# ESP32-S3 register map
Vendor: ESPRESSIF SYSTEMS (SHANGHAI) CO., LTD.; Series: ESP32 S-Series; File version: 22
CPU: Xtensa LX7 r0p0, little endian, no MPU, FPU, 0 interrupt priority bits
Address unit: 32 bits
Registers are 32-bit, read-write, reset 0x0 unless marked. A register's access mark holds for its fields unless they carry their own. Offsets are from the block's base; [hi:lo] are bit positions; {n}, {i} and the like mark numbered series.

## SENSITIVE (part 2 of 2) — SENSITIVE Peripheral
Base 0x600C1000
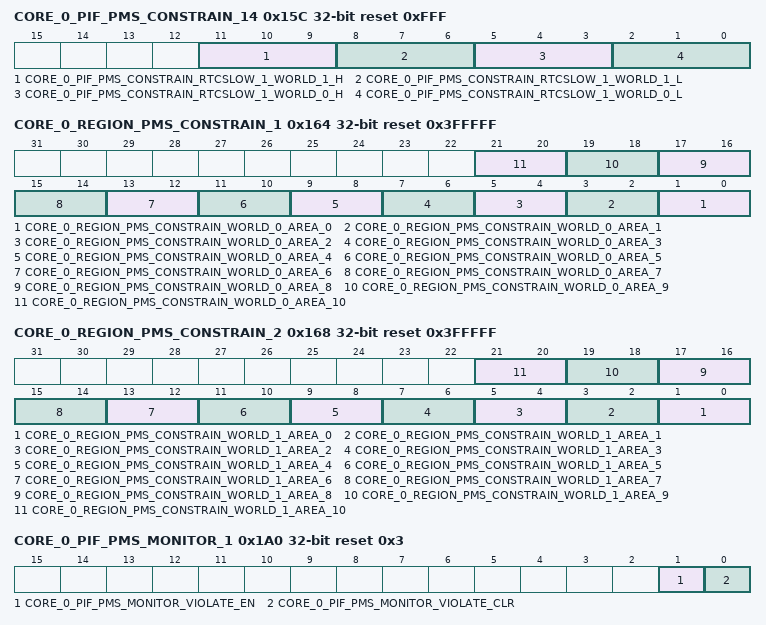
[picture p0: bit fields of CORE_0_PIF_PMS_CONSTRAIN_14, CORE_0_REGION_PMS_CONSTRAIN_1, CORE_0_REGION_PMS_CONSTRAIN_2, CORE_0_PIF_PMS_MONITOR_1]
0x15C CORE_0_PIF_PMS_CONSTRAIN_14 reset 0xFFF — Core0 access peripherals permission configuration register 14.
  [11:9] CORE_0_PIF_PMS_CONSTRAIN_RTCSLOW_1_WORLD_1_H — RTCSlow_1 memory high region permission in world 1 for core0.
  [8:6] CORE_0_PIF_PMS_CONSTRAIN_RTCSLOW_1_WORLD_1_L — RTCSlow_1 memory low region permission in world 1 for core0.
  [5:3] CORE_0_PIF_PMS_CONSTRAIN_RTCSLOW_1_WORLD_0_H — RTCSlow_1 memory high region permission in world 0 for core0.
  [2:0] CORE_0_PIF_PMS_CONSTRAIN_RTCSLOW_1_WORLD_0_L — RTCSlow_1 memory low region permission in world 0 for core0.
0x160 CORE_0_REGION_PMS_CONSTRAIN_0 — Core0 region permission register 0.
  [0] CORE_0_REGION_PMS_CONSTRAIN_LOCK — Set 1 to lock core0 region permission registers.
0x164 CORE_0_REGION_PMS_CONSTRAIN_1 reset 0x3FFFFF — Core0 region permission register 1.
  [2n+1:2n] CORE_0_REGION_PMS_CONSTRAIN_WORLD_0_AREA_{n} (n=0..10) — Region {n} permission in world 0 for core0.
0x168 CORE_0_REGION_PMS_CONSTRAIN_2 reset 0x3FFFFF — Core0 region permission register 2.
  [2n+1:2n] CORE_0_REGION_PMS_CONSTRAIN_WORLD_1_AREA_{n} (n=0..10) — Region {n} permission in world 1 for core0.
0x16C CORE_0_REGION_PMS_CONSTRAIN_3 — Core0 region permission register 3.
  [29:0] CORE_0_REGION_PMS_CONSTRAIN_ADDR_0 — Region 0 start address for core0.
{0x160+4i} CORE_0_REGION_PMS_CONSTRAIN_{i} (i=4..13) — Core0 region permission register {i}.
  [29:0] CORE_0_REGION_PMS_CONSTRAIN_ADDR_{i-3} — Region {i-4} end address and Region {i-3} start address for core0.
0x198 CORE_0_REGION_PMS_CONSTRAIN_14 — Core0 region permission register 14.
  [29:0] CORE_0_REGION_PMS_CONSTRAIN_ADDR_11 — Region 10 end address for core0.
0x19C CORE_0_PIF_PMS_MONITOR_0 — Core0 permission report register 0.
  [0] CORE_0_PIF_PMS_MONITOR_LOCK — Set 1 to lock core0 permission report registers.
0x1A0 CORE_0_PIF_PMS_MONITOR_1 reset 0x3 — Core0 permission report register 1.
  [1] CORE_0_PIF_PMS_MONITOR_VIOLATE_EN — Set 1 to enable interrupt that core0 initiate illegal PIF bus access.
  [0] CORE_0_PIF_PMS_MONITOR_VIOLATE_CLR — Set 1 to clear interrupt that core0 initiate illegal PIF bus access.
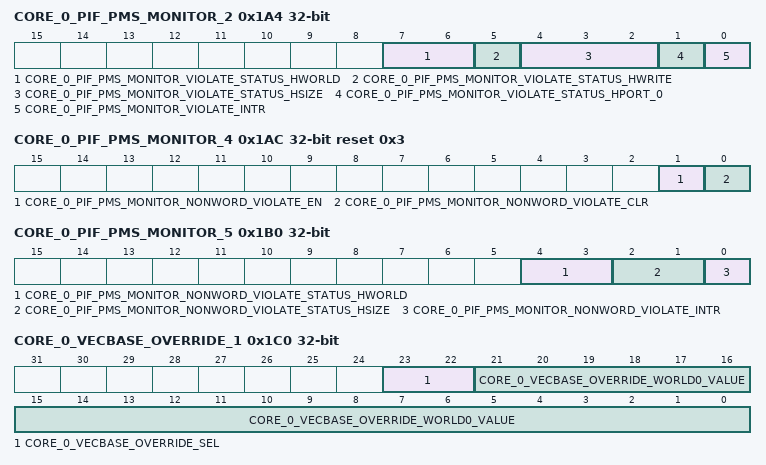
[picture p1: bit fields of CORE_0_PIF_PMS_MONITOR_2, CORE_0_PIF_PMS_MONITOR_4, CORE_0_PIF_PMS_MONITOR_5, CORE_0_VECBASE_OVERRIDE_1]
0x1A4 CORE_0_PIF_PMS_MONITOR_2 ro — Core0 permission report register 2.
  [7:6] CORE_0_PIF_PMS_MONITOR_VIOLATE_STATUS_HWORLD — Record world information when core0 initiate illegal access.
  [5] CORE_0_PIF_PMS_MONITOR_VIOLATE_STATUS_HWRITE — Record access direction when core0 initiate illegal access.
  [4:2] CORE_0_PIF_PMS_MONITOR_VIOLATE_STATUS_HSIZE — Record access type when core0 initate illegal access.
  [1] CORE_0_PIF_PMS_MONITOR_VIOLATE_STATUS_HPORT_0 — Record hport information when core0 initiate illegal access.
  [0] CORE_0_PIF_PMS_MONITOR_VIOLATE_INTR — Record core0 illegal access interrupt state.
0x1A8 CORE_0_PIF_PMS_MONITOR_3 ro — Core0 permission report register 3.
  [31:0] CORE_0_PIF_PMS_MONITOR_VIOLATE_STATUS_HADDR — Record address information when core0 initiate illegal access.
0x1AC CORE_0_PIF_PMS_MONITOR_4 reset 0x3 — Core0 permission report register 4.
  [1] CORE_0_PIF_PMS_MONITOR_NONWORD_VIOLATE_EN — Set 1 to enable interrupt that core0 initiate unsupported access type.
  [0] CORE_0_PIF_PMS_MONITOR_NONWORD_VIOLATE_CLR — Set 1 to clear interrupt that core0 initiate unsupported access type.
0x1B0 CORE_0_PIF_PMS_MONITOR_5 ro — Core0 permission report register 5.
  [4:3] CORE_0_PIF_PMS_MONITOR_NONWORD_VIOLATE_STATUS_HWORLD — Record world information when core0 initiate unsupported access type.
  [2:1] CORE_0_PIF_PMS_MONITOR_NONWORD_VIOLATE_STATUS_HSIZE — Record access type when core0 initiate unsupported access type.
  [0] CORE_0_PIF_PMS_MONITOR_NONWORD_VIOLATE_INTR — Record core0 unsupported access type interrupt state.
0x1B4 CORE_0_PIF_PMS_MONITOR_6 ro — Core0 permission report register 6.
  [31:0] CORE_0_PIF_PMS_MONITOR_NONWORD_VIOLATE_STATUS_HADDR — Record address information when core0 initiate unsupported access type.
0x1B8 CORE_0_VECBASE_OVERRIDE_LOCK — core0 vecbase override configuration register 0
  [0] CORE_0_VECBASE_OVERRIDE_LOCK — Set 1 to lock core0 vecbase configuration register
0x1BC CORE_0_VECBASE_OVERRIDE_0 reset 0x1 — core0 vecbase override configuration register 0
  [0] CORE_0_VECBASE_WORLD_MASK — Set 1 to mask world, then only world0_value will work.
0x1C0 CORE_0_VECBASE_OVERRIDE_1 — core0 vecbase override configuration register 1
  [23:22] CORE_0_VECBASE_OVERRIDE_SEL — Set 0x3 to sel vecbase_override to override vecbase register.
  [21:0] CORE_0_VECBASE_OVERRIDE_WORLD0_VALUE — world0 vecbase_override register, when core0 in world0 use this register to override vecbase register.
0x1C4 CORE_0_VECBASE_OVERRIDE_2 — core0 vecbase override configuration register 1
  [21:0] CORE_0_VECBASE_OVERRIDE_WORLD1_VALUE — world1 vecbase_override register, when core0 in world1 use this register to override vecbase register.
0x1C8 CORE_0_TOOMANYEXCEPTIONS_M_OVERRIDE_0 — core0 toomanyexception override configuration register 0.
  [0] CORE_0_TOOMANYEXCEPTIONS_M_OVERRIDE_LOCK — Set 1 to lock core0 toomanyexception override configuration register
0x1CC CORE_0_TOOMANYEXCEPTIONS_M_OVERRIDE_1 reset 0x1 — core0 toomanyexception override configuration register 1.
  [0] CORE_0_TOOMANYEXCEPTIONS_M_OVERRIDE — Set 1 to mask toomanyexception.
0x1D0 CORE_1_PIF_PMS_CONSTRAIN_0 — Core1 access peripherals permission configuration register 0.
  [0] CORE_1_PIF_PMS_CONSTRAIN_LOCK — Set 1 to lock core1 pif permission configuration register.
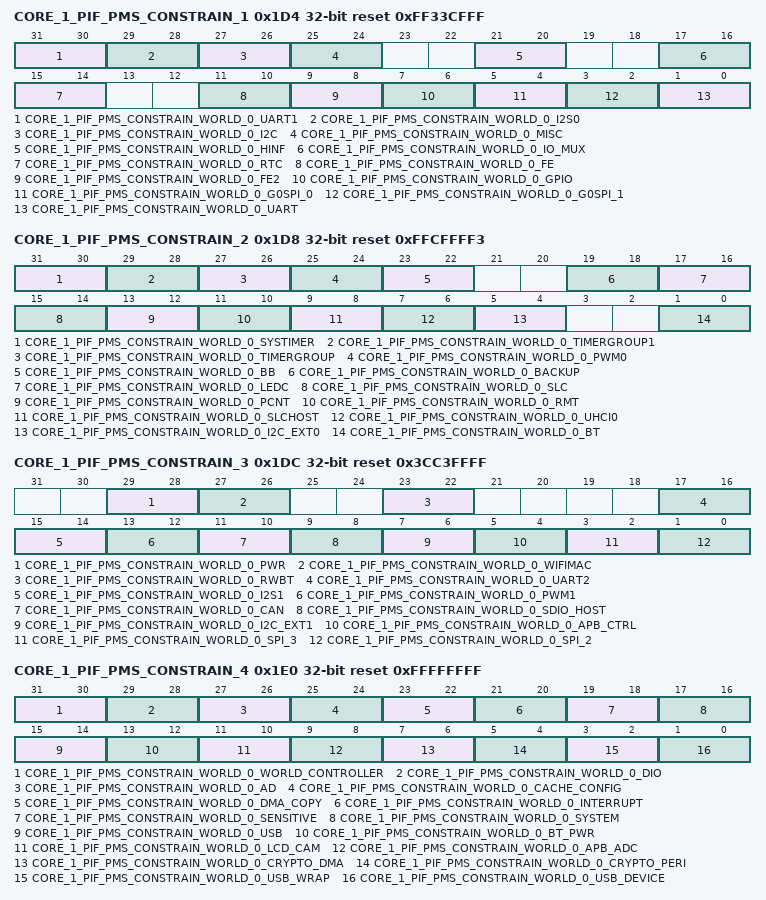
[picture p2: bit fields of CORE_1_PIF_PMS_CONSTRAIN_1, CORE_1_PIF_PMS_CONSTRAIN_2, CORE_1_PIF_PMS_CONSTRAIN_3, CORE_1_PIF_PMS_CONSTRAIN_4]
0x1D4 CORE_1_PIF_PMS_CONSTRAIN_1 reset 0xFF33CFFF — Core1 access peripherals permission configuration register 1.
  [31:30] CORE_1_PIF_PMS_CONSTRAIN_WORLD_0_UART1 — Core1 access uart1 permission in world0.
  [29:28] CORE_1_PIF_PMS_CONSTRAIN_WORLD_0_I2S0 — Core1 access i2s0 permission in world0.
  [27:26] CORE_1_PIF_PMS_CONSTRAIN_WORLD_0_I2C — Core1 access i2c permission in world0.
  [25:24] CORE_1_PIF_PMS_CONSTRAIN_WORLD_0_MISC — Core1 access misc permission in world0.
  [21:20] CORE_1_PIF_PMS_CONSTRAIN_WORLD_0_HINF — Core1 access hinf permission in world0.
  [17:16] CORE_1_PIF_PMS_CONSTRAIN_WORLD_0_IO_MUX — Core1 access io_mux permission in world0.
  [15:14] CORE_1_PIF_PMS_CONSTRAIN_WORLD_0_RTC — Core1 access rtc permission in world0.
  [11:10] CORE_1_PIF_PMS_CONSTRAIN_WORLD_0_FE — Core1 access fe permission in world0.
  [9:8] CORE_1_PIF_PMS_CONSTRAIN_WORLD_0_FE2 — Core1 access fe2 permission in world0.
  [7:6] CORE_1_PIF_PMS_CONSTRAIN_WORLD_0_GPIO — Core1 access gpio permission in world0.
  [5:4] CORE_1_PIF_PMS_CONSTRAIN_WORLD_0_G0SPI_0 — Core1 access g0spi_0 permission in world0.
  [3:2] CORE_1_PIF_PMS_CONSTRAIN_WORLD_0_G0SPI_1 — Core1 access g0spi_1 permission in world0.
  [1:0] CORE_1_PIF_PMS_CONSTRAIN_WORLD_0_UART — Core1 access uart permission in world0.
0x1D8 CORE_1_PIF_PMS_CONSTRAIN_2 reset 0xFFCFFFF3 — Core1 access peripherals permission configuration register 2.
  [31:30] CORE_1_PIF_PMS_CONSTRAIN_WORLD_0_SYSTIMER — Core1 access systimer permission in world0.
  [29:28] CORE_1_PIF_PMS_CONSTRAIN_WORLD_0_TIMERGROUP1 — Core1 access timergroup1 permission in world0.
  [27:26] CORE_1_PIF_PMS_CONSTRAIN_WORLD_0_TIMERGROUP — Core1 access timergroup permission in world0.
  [25:24] CORE_1_PIF_PMS_CONSTRAIN_WORLD_0_PWM0 — Core1 access pwm0 permission in world0.
  [23:22] CORE_1_PIF_PMS_CONSTRAIN_WORLD_0_BB — Core1 access bb permission in world0.
  [19:18] CORE_1_PIF_PMS_CONSTRAIN_WORLD_0_BACKUP — Core1 access backup permission in world0.
  [17:16] CORE_1_PIF_PMS_CONSTRAIN_WORLD_0_LEDC — Core1 access ledc permission in world0.
  [15:14] CORE_1_PIF_PMS_CONSTRAIN_WORLD_0_SLC — Core1 access slc permission in world0.
  [13:12] CORE_1_PIF_PMS_CONSTRAIN_WORLD_0_PCNT — Core1 access pcnt permission in world0.
  [11:10] CORE_1_PIF_PMS_CONSTRAIN_WORLD_0_RMT — Core1 access rmt permission in world0.
  [9:8] CORE_1_PIF_PMS_CONSTRAIN_WORLD_0_SLCHOST — Core1 access slchost permission in world0.
  [7:6] CORE_1_PIF_PMS_CONSTRAIN_WORLD_0_UHCI0 — Core1 access uhci0 permission in world0.
  [5:4] CORE_1_PIF_PMS_CONSTRAIN_WORLD_0_I2C_EXT0 — Core1 access i2c_ext0 permission in world0.
  [1:0] CORE_1_PIF_PMS_CONSTRAIN_WORLD_0_BT — Core1 access bt permission in world0.
0x1DC CORE_1_PIF_PMS_CONSTRAIN_3 reset 0x3CC3FFFF — Core1 access peripherals permission configuration register 3.
  [29:28] CORE_1_PIF_PMS_CONSTRAIN_WORLD_0_PWR — Core1 access pwr permission in world0.
  [27:26] CORE_1_PIF_PMS_CONSTRAIN_WORLD_0_WIFIMAC — Core1 access wifimac permission in world0.
  [23:22] CORE_1_PIF_PMS_CONSTRAIN_WORLD_0_RWBT — Core1 access rwbt permission in world0.
  [17:16] CORE_1_PIF_PMS_CONSTRAIN_WORLD_0_UART2 — Core1 access uart2 permission in world0.
  [15:14] CORE_1_PIF_PMS_CONSTRAIN_WORLD_0_I2S1 — Core1 access i2s1 permission in world0.
  [13:12] CORE_1_PIF_PMS_CONSTRAIN_WORLD_0_PWM1 — Core1 access pwm1 permission in world0.
  [11:10] CORE_1_PIF_PMS_CONSTRAIN_WORLD_0_CAN — Core1 access can permission in world0.
  [9:8] CORE_1_PIF_PMS_CONSTRAIN_WORLD_0_SDIO_HOST — Core1 access sdio_host permission in world0.
  [7:6] CORE_1_PIF_PMS_CONSTRAIN_WORLD_0_I2C_EXT1 — Core1 access i2c_ext1 permission in world0.
  [5:4] CORE_1_PIF_PMS_CONSTRAIN_WORLD_0_APB_CTRL — Core1 access apb_ctrl permission in world0.
  [3:2] CORE_1_PIF_PMS_CONSTRAIN_WORLD_0_SPI_3 — Core1 access spi_3 permission in world0.
  [1:0] CORE_1_PIF_PMS_CONSTRAIN_WORLD_0_SPI_2 — Core1 access spi_2 permission in world0.
0x1E0 CORE_1_PIF_PMS_CONSTRAIN_4 reset 0xFFFFFFFF — Core1 access peripherals permission configuration register 4.
  [31:30] CORE_1_PIF_PMS_CONSTRAIN_WORLD_0_WORLD_CONTROLLER — Core1 access world_controller permission in world0.
  [29:28] CORE_1_PIF_PMS_CONSTRAIN_WORLD_0_DIO — Core1 access dio permission in world0.
  [27:26] CORE_1_PIF_PMS_CONSTRAIN_WORLD_0_AD — Core1 access ad permission in world0.
  [25:24] CORE_1_PIF_PMS_CONSTRAIN_WORLD_0_CACHE_CONFIG — Core1 access cache_config permission in world0.
  [23:22] CORE_1_PIF_PMS_CONSTRAIN_WORLD_0_DMA_COPY — Core1 access dma_copy permission in world0.
  [21:20] CORE_1_PIF_PMS_CONSTRAIN_WORLD_0_INTERRUPT — Core1 access interrupt permission in world0.
  [19:18] CORE_1_PIF_PMS_CONSTRAIN_WORLD_0_SENSITIVE — Core1 access sensitive permission in world0.
  [17:16] CORE_1_PIF_PMS_CONSTRAIN_WORLD_0_SYSTEM — Core1 access system permission in world0.
  [15:14] CORE_1_PIF_PMS_CONSTRAIN_WORLD_0_USB — Core1 access usb permission in world0.
  [13:12] CORE_1_PIF_PMS_CONSTRAIN_WORLD_0_BT_PWR — Core1 access bt_pwr permission in world0.
  [11:10] CORE_1_PIF_PMS_CONSTRAIN_WORLD_0_LCD_CAM — Core1 access lcd_cam permission in world0.
  [9:8] CORE_1_PIF_PMS_CONSTRAIN_WORLD_0_APB_ADC — Core1 access apb_adc permission in world0.
  [7:6] CORE_1_PIF_PMS_CONSTRAIN_WORLD_0_CRYPTO_DMA — Core1 access crypto_dma permission in world0.
  [5:4] CORE_1_PIF_PMS_CONSTRAIN_WORLD_0_CRYPTO_PERI — Core1 access crypto_peri permission in world0.
  [3:2] CORE_1_PIF_PMS_CONSTRAIN_WORLD_0_USB_WRAP — Core1 access usb_wrap permission in world0.
  [1:0] CORE_1_PIF_PMS_CONSTRAIN_WORLD_0_USB_DEVICE — Core1 access usb_device permission in world0.
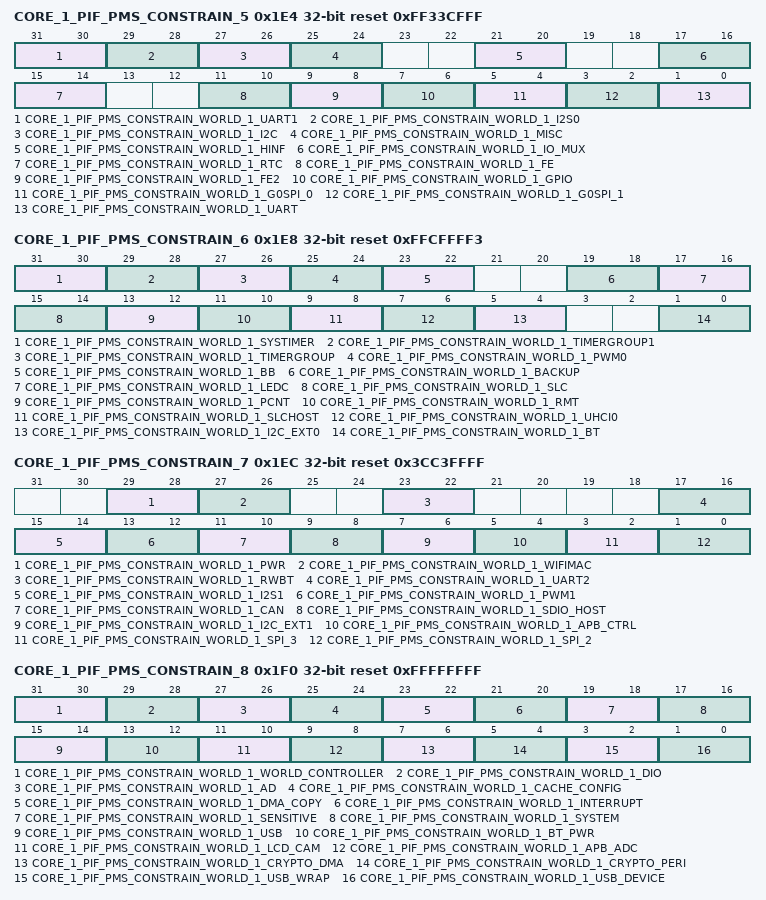
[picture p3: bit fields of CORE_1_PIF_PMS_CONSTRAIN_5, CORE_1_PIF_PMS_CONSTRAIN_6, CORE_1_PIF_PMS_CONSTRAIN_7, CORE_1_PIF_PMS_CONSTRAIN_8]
0x1E4 CORE_1_PIF_PMS_CONSTRAIN_5 reset 0xFF33CFFF — Core1 access peripherals permission configuration register 5.
  [31:30] CORE_1_PIF_PMS_CONSTRAIN_WORLD_1_UART1 — Core1 access uart1 permission in world1.
  [29:28] CORE_1_PIF_PMS_CONSTRAIN_WORLD_1_I2S0 — Core1 access i2s0 permission in world1.
  [27:26] CORE_1_PIF_PMS_CONSTRAIN_WORLD_1_I2C — Core1 access i2c permission in world1.
  [25:24] CORE_1_PIF_PMS_CONSTRAIN_WORLD_1_MISC — Core1 access misc permission in world1.
  [21:20] CORE_1_PIF_PMS_CONSTRAIN_WORLD_1_HINF — Core1 access hinf permission in world1.
  [17:16] CORE_1_PIF_PMS_CONSTRAIN_WORLD_1_IO_MUX — Core1 access io_mux permission in world1.
  [15:14] CORE_1_PIF_PMS_CONSTRAIN_WORLD_1_RTC — Core1 access rtc permission in world1.
  [11:10] CORE_1_PIF_PMS_CONSTRAIN_WORLD_1_FE — Core1 access fe permission in world1.
  [9:8] CORE_1_PIF_PMS_CONSTRAIN_WORLD_1_FE2 — Core1 access fe2 permission in world1.
  [7:6] CORE_1_PIF_PMS_CONSTRAIN_WORLD_1_GPIO — Core1 access gpio permission in world1.
  [5:4] CORE_1_PIF_PMS_CONSTRAIN_WORLD_1_G0SPI_0 — Core1 access g0spi_0 permission in world1.
  [3:2] CORE_1_PIF_PMS_CONSTRAIN_WORLD_1_G0SPI_1 — Core1 access g0spi_1 permission in world1.
  [1:0] CORE_1_PIF_PMS_CONSTRAIN_WORLD_1_UART — Core1 access uart permission in world1.
0x1E8 CORE_1_PIF_PMS_CONSTRAIN_6 reset 0xFFCFFFF3 — Core1 access peripherals permission configuration register 6.
  [31:30] CORE_1_PIF_PMS_CONSTRAIN_WORLD_1_SYSTIMER — Core1 access systimer permission in world1.
  [29:28] CORE_1_PIF_PMS_CONSTRAIN_WORLD_1_TIMERGROUP1 — Core1 access timergroup1 permission in world1.
  [27:26] CORE_1_PIF_PMS_CONSTRAIN_WORLD_1_TIMERGROUP — Core1 access timergroup permission in world1.
  [25:24] CORE_1_PIF_PMS_CONSTRAIN_WORLD_1_PWM0 — Core1 access pwm0 permission in world1.
  [23:22] CORE_1_PIF_PMS_CONSTRAIN_WORLD_1_BB — Core1 access bb permission in world1.
  [19:18] CORE_1_PIF_PMS_CONSTRAIN_WORLD_1_BACKUP — Core1 access backup permission in world1.
  [17:16] CORE_1_PIF_PMS_CONSTRAIN_WORLD_1_LEDC — Core1 access ledc permission in world1.
  [15:14] CORE_1_PIF_PMS_CONSTRAIN_WORLD_1_SLC — Core1 access slc permission in world1.
  [13:12] CORE_1_PIF_PMS_CONSTRAIN_WORLD_1_PCNT — Core1 access pcnt permission in world1.
  [11:10] CORE_1_PIF_PMS_CONSTRAIN_WORLD_1_RMT — Core1 access rmt permission in world1.
  [9:8] CORE_1_PIF_PMS_CONSTRAIN_WORLD_1_SLCHOST — Core1 access slchost permission in world1.
  [7:6] CORE_1_PIF_PMS_CONSTRAIN_WORLD_1_UHCI0 — Core1 access uhci0 permission in world1.
  [5:4] CORE_1_PIF_PMS_CONSTRAIN_WORLD_1_I2C_EXT0 — Core1 access i2c_ext0 permission in world1.
  [1:0] CORE_1_PIF_PMS_CONSTRAIN_WORLD_1_BT — Core1 access bt permission in world1.
0x1EC CORE_1_PIF_PMS_CONSTRAIN_7 reset 0x3CC3FFFF — Core1 access peripherals permission configuration register 7.
  [29:28] CORE_1_PIF_PMS_CONSTRAIN_WORLD_1_PWR — Core1 access pwr permission in world1.
  [27:26] CORE_1_PIF_PMS_CONSTRAIN_WORLD_1_WIFIMAC — Core1 access wifimac permission in world1.
  [23:22] CORE_1_PIF_PMS_CONSTRAIN_WORLD_1_RWBT — Core1 access rwbt permission in world1.
  [17:16] CORE_1_PIF_PMS_CONSTRAIN_WORLD_1_UART2 — Core1 access uart2 permission in world1.
  [15:14] CORE_1_PIF_PMS_CONSTRAIN_WORLD_1_I2S1 — Core1 access i2s1 permission in world1.
  [13:12] CORE_1_PIF_PMS_CONSTRAIN_WORLD_1_PWM1 — Core1 access pwm1 permission in world1.
  [11:10] CORE_1_PIF_PMS_CONSTRAIN_WORLD_1_CAN — Core1 access can permission in world1.
  [9:8] CORE_1_PIF_PMS_CONSTRAIN_WORLD_1_SDIO_HOST — Core1 access sdio_host permission in world1.
  [7:6] CORE_1_PIF_PMS_CONSTRAIN_WORLD_1_I2C_EXT1 — Core1 access i2c_ext1 permission in world1.
  [5:4] CORE_1_PIF_PMS_CONSTRAIN_WORLD_1_APB_CTRL — Core1 access apb_ctrl permission in world1.
  [3:2] CORE_1_PIF_PMS_CONSTRAIN_WORLD_1_SPI_3 — Core1 access spi_3 permission in world1.
  [1:0] CORE_1_PIF_PMS_CONSTRAIN_WORLD_1_SPI_2 — Core1 access spi_2 permission in world1.
0x1F0 CORE_1_PIF_PMS_CONSTRAIN_8 reset 0xFFFFFFFF — Core1 access peripherals permission configuration register 8.
  [31:30] CORE_1_PIF_PMS_CONSTRAIN_WORLD_1_WORLD_CONTROLLER — Core1 access world_controller permission in world1.
  [29:28] CORE_1_PIF_PMS_CONSTRAIN_WORLD_1_DIO — Core1 access dio permission in world1.
  [27:26] CORE_1_PIF_PMS_CONSTRAIN_WORLD_1_AD — Core1 access ad permission in world1.
  [25:24] CORE_1_PIF_PMS_CONSTRAIN_WORLD_1_CACHE_CONFIG — Core1 access cache_config permission in world1.
  [23:22] CORE_1_PIF_PMS_CONSTRAIN_WORLD_1_DMA_COPY — Core1 access dma_copy permission in world1.
  [21:20] CORE_1_PIF_PMS_CONSTRAIN_WORLD_1_INTERRUPT — Core1 access interrupt permission in world1.
  [19:18] CORE_1_PIF_PMS_CONSTRAIN_WORLD_1_SENSITIVE — Core1 access sensitive permission in world1.
  [17:16] CORE_1_PIF_PMS_CONSTRAIN_WORLD_1_SYSTEM — Core1 access system permission in world1.
  [15:14] CORE_1_PIF_PMS_CONSTRAIN_WORLD_1_USB — Core1 access usb permission in world1.
  [13:12] CORE_1_PIF_PMS_CONSTRAIN_WORLD_1_BT_PWR — Core1 access bt_pwr permission in world1.
  [11:10] CORE_1_PIF_PMS_CONSTRAIN_WORLD_1_LCD_CAM — Core1 access lcd_cam permission in world1.
  [9:8] CORE_1_PIF_PMS_CONSTRAIN_WORLD_1_APB_ADC — Core1 access apb_adc permission in world1.
  [7:6] CORE_1_PIF_PMS_CONSTRAIN_WORLD_1_CRYPTO_DMA — Core1 access crypto_dma permission in world1.
  [5:4] CORE_1_PIF_PMS_CONSTRAIN_WORLD_1_CRYPTO_PERI — Core1 access crypto_peri permission in world1.
  [3:2] CORE_1_PIF_PMS_CONSTRAIN_WORLD_1_USB_WRAP — Core1 access usb_wrap permission in world1.
  [1:0] CORE_1_PIF_PMS_CONSTRAIN_WORLD_1_USB_DEVICE — Core1 access usb_device permission in world1.
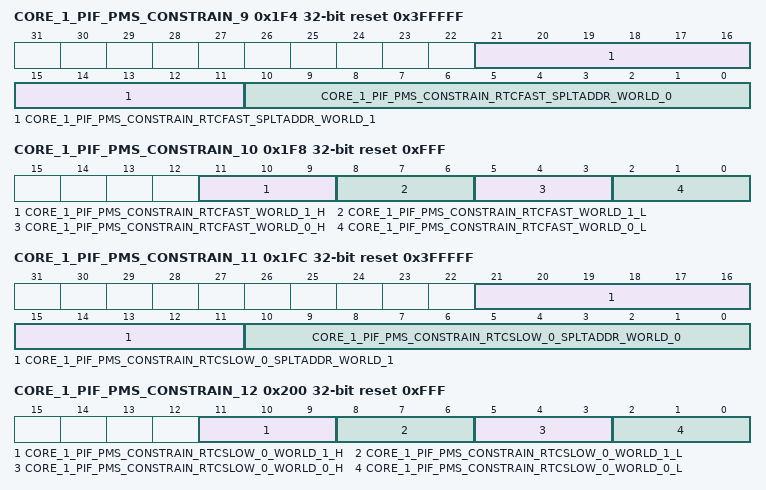
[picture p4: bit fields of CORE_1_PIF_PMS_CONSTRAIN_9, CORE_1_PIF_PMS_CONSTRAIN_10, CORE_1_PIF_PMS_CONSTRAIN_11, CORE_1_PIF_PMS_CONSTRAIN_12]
0x1F4 CORE_1_PIF_PMS_CONSTRAIN_9 reset 0x3FFFFF — Core1 access peripherals permission configuration register 9.
  [21:11] CORE_1_PIF_PMS_CONSTRAIN_RTCFAST_SPLTADDR_WORLD_1 — RTCFast memory split address in world 1 for core1.
  [10:0] CORE_1_PIF_PMS_CONSTRAIN_RTCFAST_SPLTADDR_WORLD_0 — RTCFast memory split address in world 0 for core1.
0x1F8 CORE_1_PIF_PMS_CONSTRAIN_10 reset 0xFFF — core1 access peripherals permission configuration register 10.
  [11:9] CORE_1_PIF_PMS_CONSTRAIN_RTCFAST_WORLD_1_H — RTCFast memory high region permission in world 1 for core1.
  [8:6] CORE_1_PIF_PMS_CONSTRAIN_RTCFAST_WORLD_1_L — RTCFast memory low region permission in world 1 for core1.
  [5:3] CORE_1_PIF_PMS_CONSTRAIN_RTCFAST_WORLD_0_H — RTCFast memory high region permission in world 0 for core1.
  [2:0] CORE_1_PIF_PMS_CONSTRAIN_RTCFAST_WORLD_0_L — RTCFast memory low region permission in world 0 for core1.
0x1FC CORE_1_PIF_PMS_CONSTRAIN_11 reset 0x3FFFFF — core1 access peripherals permission configuration register 11.
  [21:11] CORE_1_PIF_PMS_CONSTRAIN_RTCSLOW_0_SPLTADDR_WORLD_1 — RTCSlow_0 memory split address in world 1 for core1.
  [10:0] CORE_1_PIF_PMS_CONSTRAIN_RTCSLOW_0_SPLTADDR_WORLD_0 — RTCSlow_0 memory split address in world 0 for core1.
0x200 CORE_1_PIF_PMS_CONSTRAIN_12 reset 0xFFF — core1 access peripherals permission configuration register 12.
  [11:9] CORE_1_PIF_PMS_CONSTRAIN_RTCSLOW_0_WORLD_1_H — RTCSlow_0 memory high region permission in world 1 for core1.
  [8:6] CORE_1_PIF_PMS_CONSTRAIN_RTCSLOW_0_WORLD_1_L — RTCSlow_0 memory low region permission in world 1 for core1.
  [5:3] CORE_1_PIF_PMS_CONSTRAIN_RTCSLOW_0_WORLD_0_H — RTCSlow_0 memory high region permission in world 0 for core1.
  [2:0] CORE_1_PIF_PMS_CONSTRAIN_RTCSLOW_0_WORLD_0_L — RTCSlow_0 memory low region permission in world 0 for core1.
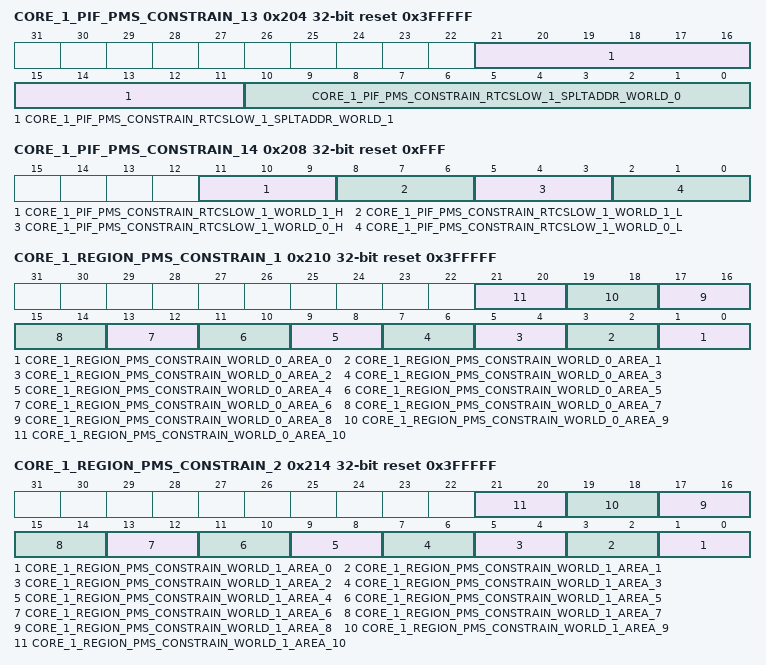
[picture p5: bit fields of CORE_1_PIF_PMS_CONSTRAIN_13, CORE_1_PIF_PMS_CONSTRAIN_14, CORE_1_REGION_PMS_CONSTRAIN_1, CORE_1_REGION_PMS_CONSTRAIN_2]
0x204 CORE_1_PIF_PMS_CONSTRAIN_13 reset 0x3FFFFF — core1 access peripherals permission configuration register 13.
  [21:11] CORE_1_PIF_PMS_CONSTRAIN_RTCSLOW_1_SPLTADDR_WORLD_1 — RTCSlow_1 memory split address in world 1 for core1.
  [10:0] CORE_1_PIF_PMS_CONSTRAIN_RTCSLOW_1_SPLTADDR_WORLD_0 — RTCSlow_1 memory split address in world 0 for core1.
0x208 CORE_1_PIF_PMS_CONSTRAIN_14 reset 0xFFF — core1 access peripherals permission configuration register 14.
  [11:9] CORE_1_PIF_PMS_CONSTRAIN_RTCSLOW_1_WORLD_1_H — RTCSlow_1 memory high region permission in world 1 for core1.
  [8:6] CORE_1_PIF_PMS_CONSTRAIN_RTCSLOW_1_WORLD_1_L — RTCSlow_1 memory low region permission in world 1 for core1.
  [5:3] CORE_1_PIF_PMS_CONSTRAIN_RTCSLOW_1_WORLD_0_H — RTCSlow_1 memory high region permission in world 0 for core1.
  [2:0] CORE_1_PIF_PMS_CONSTRAIN_RTCSLOW_1_WORLD_0_L — RTCSlow_1 memory low region permission in world 0 for core1.
0x20C CORE_1_REGION_PMS_CONSTRAIN_0 — core1 region permission register 0.
  [0] CORE_1_REGION_PMS_CONSTRAIN_LOCK — Set 1 to lock core1 region permission registers.
0x210 CORE_1_REGION_PMS_CONSTRAIN_1 reset 0x3FFFFF — core1 region permission register 1.
  [2n+1:2n] CORE_1_REGION_PMS_CONSTRAIN_WORLD_0_AREA_{n} (n=0..10) — Region {n} permission in world 0 for core1.
0x214 CORE_1_REGION_PMS_CONSTRAIN_2 reset 0x3FFFFF — core1 region permission register 2.
  [2n+1:2n] CORE_1_REGION_PMS_CONSTRAIN_WORLD_1_AREA_{n} (n=0..10) — Region {n} permission in world 1 for core1.
0x218 CORE_1_REGION_PMS_CONSTRAIN_3 — core1 region permission register 3.
  [29:0] CORE_1_REGION_PMS_CONSTRAIN_ADDR_0 — Region 0 start address for core1.
{0x20C+4i} CORE_1_REGION_PMS_CONSTRAIN_{i} (i=4..13) — core1 region permission register {i}.
  [29:0] CORE_1_REGION_PMS_CONSTRAIN_ADDR_{i-3} — Region {i-4} end address and Region {i-3} start address for core1.
0x244 CORE_1_REGION_PMS_CONSTRAIN_14 — core1 region permission register 14.
  [29:0] CORE_1_REGION_PMS_CONSTRAIN_ADDR_11 — Region 10 end address for core1.
0x248 CORE_1_PIF_PMS_MONITOR_0 — core1 permission report register 0.
  [0] CORE_1_PIF_PMS_MONITOR_LOCK — Set 1 to lock core1 permission report registers.
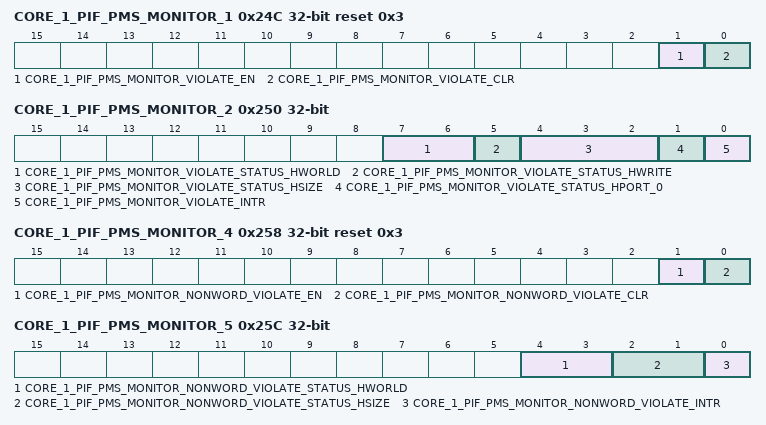
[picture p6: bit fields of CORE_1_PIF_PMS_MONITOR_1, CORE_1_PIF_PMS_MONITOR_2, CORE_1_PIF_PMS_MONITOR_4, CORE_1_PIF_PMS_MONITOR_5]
0x24C CORE_1_PIF_PMS_MONITOR_1 reset 0x3 — core1 permission report register 1.
  [1] CORE_1_PIF_PMS_MONITOR_VIOLATE_EN — Set 1 to enable interrupt that core1 initiate illegal PIF bus access.
  [0] CORE_1_PIF_PMS_MONITOR_VIOLATE_CLR — Set 1 to clear interrupt that core1 initiate illegal PIF bus access.
0x250 CORE_1_PIF_PMS_MONITOR_2 ro — core1 permission report register 2.
  [7:6] CORE_1_PIF_PMS_MONITOR_VIOLATE_STATUS_HWORLD — Record world information when core1 initiate illegal access.
  [5] CORE_1_PIF_PMS_MONITOR_VIOLATE_STATUS_HWRITE — Record access direction when core1 initiate illegal access.
  [4:2] CORE_1_PIF_PMS_MONITOR_VIOLATE_STATUS_HSIZE — Record access type when core1 initate illegal access.
  [1] CORE_1_PIF_PMS_MONITOR_VIOLATE_STATUS_HPORT_0 — Record hport information when core1 initiate illegal access.
  [0] CORE_1_PIF_PMS_MONITOR_VIOLATE_INTR — Record core1 illegal access interrupt state.
0x254 CORE_1_PIF_PMS_MONITOR_3 ro — core1 permission report register 3.
  [31:0] CORE_1_PIF_PMS_MONITOR_VIOLATE_STATUS_HADDR — Record address information when core1 initiate illegal access.
0x258 CORE_1_PIF_PMS_MONITOR_4 reset 0x3 — core1 permission report register 4.
  [1] CORE_1_PIF_PMS_MONITOR_NONWORD_VIOLATE_EN — Set 1 to enable interrupt that core1 initiate unsupported access type.
  [0] CORE_1_PIF_PMS_MONITOR_NONWORD_VIOLATE_CLR — Set 1 to clear interrupt that core1 initiate unsupported access type.
0x25C CORE_1_PIF_PMS_MONITOR_5 ro — core1 permission report register 5.
  [4:3] CORE_1_PIF_PMS_MONITOR_NONWORD_VIOLATE_STATUS_HWORLD — Record world information when core1 initiate unsupported access type.
  [2:1] CORE_1_PIF_PMS_MONITOR_NONWORD_VIOLATE_STATUS_HSIZE — Record access type when core1 initiate unsupported access type.
  [0] CORE_1_PIF_PMS_MONITOR_NONWORD_VIOLATE_INTR — Record core1 unsupported access type interrupt state.
0x260 CORE_1_PIF_PMS_MONITOR_6 ro — core1 permission report register 6.
  [31:0] CORE_1_PIF_PMS_MONITOR_NONWORD_VIOLATE_STATUS_HADDR — Record address information when core1 initiate unsupported access type.
0x264 CORE_1_VECBASE_OVERRIDE_LOCK — core1 vecbase override configuration register 0
  [0] CORE_1_VECBASE_OVERRIDE_LOCK — Set 1 to lock core1 vecbase configuration register
0x268 CORE_1_VECBASE_OVERRIDE_0 reset 0x1 — core1 vecbase override configuration register 0
  [0] CORE_1_VECBASE_WORLD_MASK — Set 1 to mask world, then only world0_value will work.
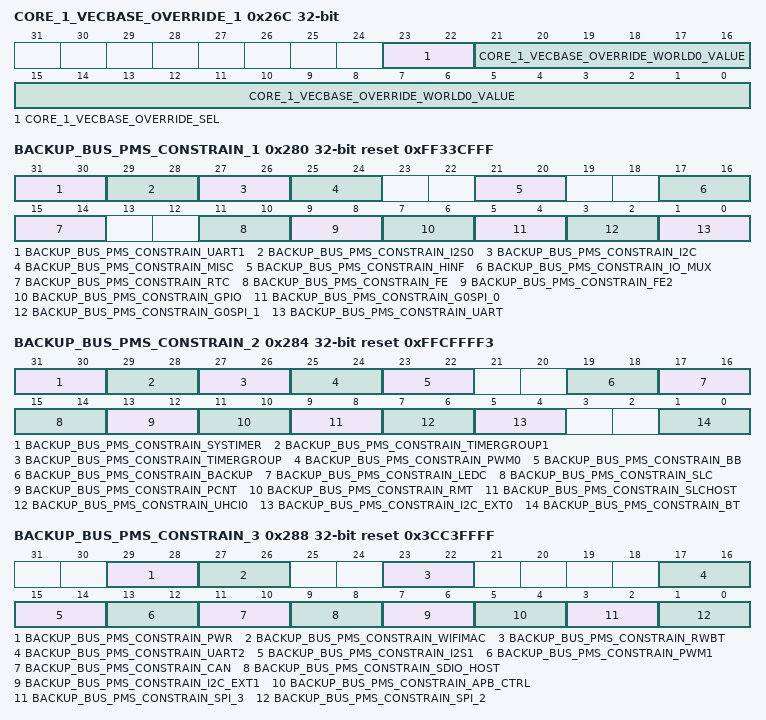
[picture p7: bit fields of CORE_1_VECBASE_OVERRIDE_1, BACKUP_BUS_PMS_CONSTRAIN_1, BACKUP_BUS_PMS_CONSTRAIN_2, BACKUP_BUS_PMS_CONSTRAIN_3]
0x26C CORE_1_VECBASE_OVERRIDE_1 — core1 vecbase override configuration register 1
  [23:22] CORE_1_VECBASE_OVERRIDE_SEL — Set 0x3 to sel vecbase_override to override vecbase register.
  [21:0] CORE_1_VECBASE_OVERRIDE_WORLD0_VALUE — world0 vecbase_override register, when core1 in world0 use this register to override vecbase register.
0x270 CORE_1_VECBASE_OVERRIDE_2 — core1 vecbase override configuration register 1
  [21:0] CORE_1_VECBASE_OVERRIDE_WORLD1_VALUE — world1 vecbase_override register, when core1 in world1 use this register to override vecbase register.
0x274 CORE_1_TOOMANYEXCEPTIONS_M_OVERRIDE_0 — core1 toomanyexception override configuration register 0.
  [0] CORE_1_TOOMANYEXCEPTIONS_M_OVERRIDE_LOCK — Set 1 to lock core1 toomanyexception override configuration register
0x278 CORE_1_TOOMANYEXCEPTIONS_M_OVERRIDE_1 reset 0x1 — core1 toomanyexception override configuration register 1.
  [0] CORE_1_TOOMANYEXCEPTIONS_M_OVERRIDE — Set 1 to mask toomanyexception.
0x27C BACKUP_BUS_PMS_CONSTRAIN_0 — BackUp access peripherals permission configuration register 0.
  [0] BACKUP_BUS_PMS_CONSTRAIN_LOCK — Set 1 to lock BackUp permission configuration registers.
0x280 BACKUP_BUS_PMS_CONSTRAIN_1 reset 0xFF33CFFF — BackUp access peripherals permission configuration register 1.
  [31:30] BACKUP_BUS_PMS_CONSTRAIN_UART1 — BackUp access uart1 permission.
  [29:28] BACKUP_BUS_PMS_CONSTRAIN_I2S0 — BackUp access i2s0 permission.
  [27:26] BACKUP_BUS_PMS_CONSTRAIN_I2C — BackUp access i2c permission.
  [25:24] BACKUP_BUS_PMS_CONSTRAIN_MISC — BackUp access misc permission.
  [21:20] BACKUP_BUS_PMS_CONSTRAIN_HINF — BackUp access hinf permission.
  [17:16] BACKUP_BUS_PMS_CONSTRAIN_IO_MUX — BackUp access io_mux permission.
  [15:14] BACKUP_BUS_PMS_CONSTRAIN_RTC — BackUp access rtc permission.
  [11:10] BACKUP_BUS_PMS_CONSTRAIN_FE — BackUp access fe permission.
  [9:8] BACKUP_BUS_PMS_CONSTRAIN_FE2 — BackUp access fe2 permission.
  [7:6] BACKUP_BUS_PMS_CONSTRAIN_GPIO — BackUp access gpio permission.
  [5:4] BACKUP_BUS_PMS_CONSTRAIN_G0SPI_0 — BackUp access g0spi_0 permission.
  [3:2] BACKUP_BUS_PMS_CONSTRAIN_G0SPI_1 — BackUp access g0spi_1 permission.
  [1:0] BACKUP_BUS_PMS_CONSTRAIN_UART — BackUp access uart permission.
0x284 BACKUP_BUS_PMS_CONSTRAIN_2 reset 0xFFCFFFF3 — BackUp access peripherals permission configuration register 2.
  [31:30] BACKUP_BUS_PMS_CONSTRAIN_SYSTIMER — BackUp access systimer permission.
  [29:28] BACKUP_BUS_PMS_CONSTRAIN_TIMERGROUP1 — BackUp access timergroup1 permission.
  [27:26] BACKUP_BUS_PMS_CONSTRAIN_TIMERGROUP — BackUp access timergroup permission.
  [25:24] BACKUP_BUS_PMS_CONSTRAIN_PWM0 — BackUp access pwm0 permission.
  [23:22] BACKUP_BUS_PMS_CONSTRAIN_BB — BackUp access bb permission.
  [19:18] BACKUP_BUS_PMS_CONSTRAIN_BACKUP — BackUp access backup permission.
  [17:16] BACKUP_BUS_PMS_CONSTRAIN_LEDC — BackUp access ledc permission.
  [15:14] BACKUP_BUS_PMS_CONSTRAIN_SLC — BackUp access slc permission.
  [13:12] BACKUP_BUS_PMS_CONSTRAIN_PCNT — BackUp access pcnt permission.
  [11:10] BACKUP_BUS_PMS_CONSTRAIN_RMT — BackUp access rmt permission.
  [9:8] BACKUP_BUS_PMS_CONSTRAIN_SLCHOST — BackUp access slchost permission.
  [7:6] BACKUP_BUS_PMS_CONSTRAIN_UHCI0 — BackUp access uhci0 permission.
  [5:4] BACKUP_BUS_PMS_CONSTRAIN_I2C_EXT0 — BackUp access i2c_ext0 permission.
  [1:0] BACKUP_BUS_PMS_CONSTRAIN_BT — BackUp access bt permission.
0x288 BACKUP_BUS_PMS_CONSTRAIN_3 reset 0x3CC3FFFF — BackUp access peripherals permission configuration register 3.
  [29:28] BACKUP_BUS_PMS_CONSTRAIN_PWR — BackUp access pwr permission.
  [27:26] BACKUP_BUS_PMS_CONSTRAIN_WIFIMAC — BackUp access wifimac permission.
  [23:22] BACKUP_BUS_PMS_CONSTRAIN_RWBT — BackUp access rwbt permission.
  [17:16] BACKUP_BUS_PMS_CONSTRAIN_UART2 — BackUp access uart2 permission.
  [15:14] BACKUP_BUS_PMS_CONSTRAIN_I2S1 — BackUp access i2s1 permission.
  [13:12] BACKUP_BUS_PMS_CONSTRAIN_PWM1 — BackUp access pwm1 permission.
  [11:10] BACKUP_BUS_PMS_CONSTRAIN_CAN — BackUp access can permission.
  [9:8] BACKUP_BUS_PMS_CONSTRAIN_SDIO_HOST — BackUp access sdio_host permission.
  [7:6] BACKUP_BUS_PMS_CONSTRAIN_I2C_EXT1 — BackUp access i2c_ext1 permission.
  [5:4] BACKUP_BUS_PMS_CONSTRAIN_APB_CTRL — BackUp access apb_ctrl permission.
  [3:2] BACKUP_BUS_PMS_CONSTRAIN_SPI_3 — BackUp access spi_3 permission.
  [1:0] BACKUP_BUS_PMS_CONSTRAIN_SPI_2 — BackUp access spi_2 permission.
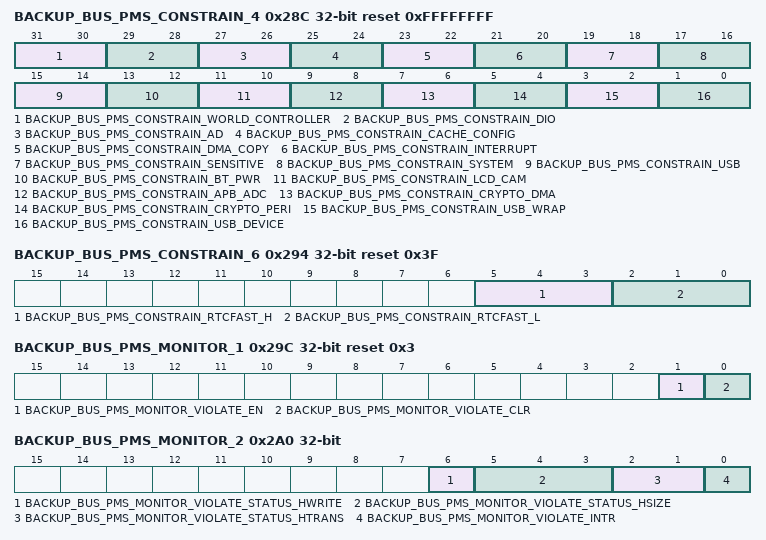
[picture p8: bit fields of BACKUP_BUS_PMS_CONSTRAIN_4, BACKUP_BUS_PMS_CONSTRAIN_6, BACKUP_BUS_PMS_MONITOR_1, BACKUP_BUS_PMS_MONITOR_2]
0x28C BACKUP_BUS_PMS_CONSTRAIN_4 reset 0xFFFFFFFF — BackUp access peripherals permission configuration register 4.
  [31:30] BACKUP_BUS_PMS_CONSTRAIN_WORLD_CONTROLLER — BackUp access world_controller permission.
  [29:28] BACKUP_BUS_PMS_CONSTRAIN_DIO — BackUp access dio permission.
  [27:26] BACKUP_BUS_PMS_CONSTRAIN_AD — BackUp access ad permission.
  [25:24] BACKUP_BUS_PMS_CONSTRAIN_CACHE_CONFIG — BackUp access cache_config permission.
  [23:22] BACKUP_BUS_PMS_CONSTRAIN_DMA_COPY — BackUp access dma_copy permission.
  [21:20] BACKUP_BUS_PMS_CONSTRAIN_INTERRUPT — BackUp access interrupt permission.
  [19:18] BACKUP_BUS_PMS_CONSTRAIN_SENSITIVE — BackUp access sensitive permission.
  [17:16] BACKUP_BUS_PMS_CONSTRAIN_SYSTEM — BackUp access system permission.
  [15:14] BACKUP_BUS_PMS_CONSTRAIN_USB — BackUp access usb permission.
  [13:12] BACKUP_BUS_PMS_CONSTRAIN_BT_PWR — BackUp access bt_pwr permission.
  [11:10] BACKUP_BUS_PMS_CONSTRAIN_LCD_CAM — BackUp access lcd_cam permission.
  [9:8] BACKUP_BUS_PMS_CONSTRAIN_APB_ADC — BackUp access apb_adc permission.
  [7:6] BACKUP_BUS_PMS_CONSTRAIN_CRYPTO_DMA — BackUp access crypto_dma permission.
  [5:4] BACKUP_BUS_PMS_CONSTRAIN_CRYPTO_PERI — BackUp access crypto_peri permission.
  [3:2] BACKUP_BUS_PMS_CONSTRAIN_USB_WRAP — BackUp access usb_wrap permission.
  [1:0] BACKUP_BUS_PMS_CONSTRAIN_USB_DEVICE — BackUp access usb_device permission.
0x290 BACKUP_BUS_PMS_CONSTRAIN_5 reset 0x7FF — BackUp access peripherals permission configuration register 5.
  [10:0] BACKUP_BUS_PMS_CONSTRAIN_RTCFAST_SPLTADDR — BackUp access rtcfast_spltaddr permission.
0x294 BACKUP_BUS_PMS_CONSTRAIN_6 reset 0x3F — BackUp access peripherals permission configuration register 6.
  [5:3] BACKUP_BUS_PMS_CONSTRAIN_RTCFAST_H — BackUp access rtcfast_h permission.
  [2:0] BACKUP_BUS_PMS_CONSTRAIN_RTCFAST_L — BackUp access rtcfast_l permission.
0x298 BACKUP_BUS_PMS_MONITOR_0 — BackUp permission report register 0.
  [0] BACKUP_BUS_PMS_MONITOR_LOCK — Set 1 to lock BackUp permission report registers.
0x29C BACKUP_BUS_PMS_MONITOR_1 reset 0x3 — BackUp permission report register 1.
  [1] BACKUP_BUS_PMS_MONITOR_VIOLATE_EN — Set 1 to enable interrupt that BackUp initiate illegal access.
  [0] BACKUP_BUS_PMS_MONITOR_VIOLATE_CLR — Set 1 to clear interrupt that BackUp initiate illegal access.
0x2A0 BACKUP_BUS_PMS_MONITOR_2 ro — BackUp permission report register 2.
  [6] BACKUP_BUS_PMS_MONITOR_VIOLATE_STATUS_HWRITE — Record access direction when BackUp initiate illegal access.
  [5:3] BACKUP_BUS_PMS_MONITOR_VIOLATE_STATUS_HSIZE — Record access type when BackUp initate illegal access.
  [2:1] BACKUP_BUS_PMS_MONITOR_VIOLATE_STATUS_HTRANS — Record htrans when BackUp initate illegal access.
  [0] BACKUP_BUS_PMS_MONITOR_VIOLATE_INTR — Record BackUp illegal access interrupt state.
0x2A4 BACKUP_BUS_PMS_MONITOR_3 ro — BackUp permission report register 3.
  [31:0] BACKUP_BUS_PMS_MONITOR_VIOLATE_HADDR — Record address information when BackUp initiate illegal access.
0x2A8 EDMA_BOUNDARY_LOCK
  [0] EDMA_BOUNDARY_LOCK — Set 1 to lock EDMA boundary registers.
0x2AC EDMA_BOUNDARY_0 — EDMA boundary 0 configuration
  [13:0] EDMA_BOUNDARY_0 — This field is used to configure the boundary 0 of external RAM. The unit is 4K. For example, set this field to 0x80, then the address boundary 0 would be 0x3C080000 (0x3C000000 + 0x80 * 4K).
0x2B0 EDMA_BOUNDARY_1 reset 0x2000 — EDMA boundary 1 configuration
  [13:0] EDMA_BOUNDARY_1 — This field is used to configure the boundary 1 of external RAM. The unit is 4K. For example, set this field to 0x80, then the address boundary 0 would be 0x3C080000 (0x3C000000 + 0x80 * 4K).
0x2B4 EDMA_BOUNDARY_2 reset 0x2000 — EDMA boundary 2 configuration
  [13:0] EDMA_BOUNDARY_2 — This field is used to configure the boundary 2 of external RAM. The unit is 4K. For example, set this field to 0x80, then the address boundary 0 would be 0x3C080000 (0x3C000000 + 0x80 * 4K).
0x2B8 EDMA_PMS_SPI2_LOCK — EDMA-SPI2 permission lock register.
  [0] EDMA_PMS_SPI2_LOCK — Set 1 to lock EDMA-SPI2 permission control registers.
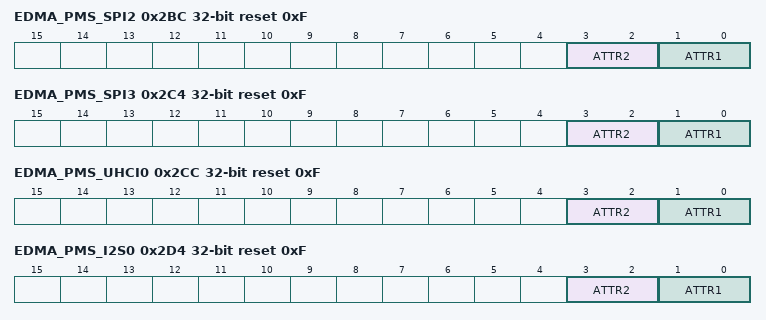
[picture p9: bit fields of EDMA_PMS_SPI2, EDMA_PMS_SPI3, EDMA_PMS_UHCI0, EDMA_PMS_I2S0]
0x2BC EDMA_PMS_SPI2 reset 0xF — EDMA-SPI2 permission control register.
  [3:2] ATTR2 — This field is used to configure the permission of SPI2 accessing address, which is larger than boundary 1 and less than boundary 2, through EDMA. Bit 0: set this bit to enable read permission. Bit 1: set this bit to enable write permission.
  [1:0] ATTR1 — This field is used to configure the permission of SPI2 accessing address, which is larger than boundary 0 and less than boundary 1, through EDMA. Bit 0: set this bit to enable read permission. Bit 1: set this bit to enable write permission.
0x2C0 EDMA_PMS_SPI3_LOCK — EDMA-SPI3 permission lock register.
  [0] EDMA_PMS_SPI3_LOCK — Set 1 to lock EDMA-SPI3 permission control registers.
0x2C4 EDMA_PMS_SPI3 reset 0xF — EDMA-SPI3 permission control register.
  [3:2] ATTR2 — This field is used to configure the permission of SPI3 accessing address, which is larger than boundary 1 and less than boundary 2, through EDMA. Bit 0: set this bit to enable read permission. Bit 1: set this bit to enable write permission.
  [1:0] ATTR1 — This field is used to configure the permission of SPI3 accessing address, which is larger than boundary 0 and less than boundary 1, through EDMA. Bit 0: set this bit to enable read permission. Bit 1: set this bit to enable write permission.
0x2C8 EDMA_PMS_UHCI0_LOCK — EDMA-UHCI0 permission lock register.
  [0] EDMA_PMS_UHCI0_LOCK — Set 1 to lock EDMA-UHCI0 permission control registers.
0x2CC EDMA_PMS_UHCI0 reset 0xF — EDMA-UHCI0 permission control register.
  [3:2] ATTR2 — This field is used to configure the permission of UHCI0 accessing address, which is larger than boundary 1 and less than boundary 2, through EDMA. Bit 0: set this bit to enable read permission. Bit 1: set this bit to enable write permission.
  [1:0] ATTR1 — This field is used to configure the permission of UHCI0 accessing address, which is larger than boundary 0 and less than boundary 1, through EDMA. Bit 0: set this bit to enable read permission. Bit 1: set this bit to enable write permission.
0x2D0 EDMA_PMS_I2S0_LOCK — EDMA-I2S0 permission lock register.
  [0] EDMA_PMS_I2S0_LOCK — Set 1 to lock EDMA-I2S0 permission control registers.
0x2D4 EDMA_PMS_I2S0 reset 0xF — EDMA-I2S0 permission control register.
  [3:2] ATTR2 — This field is used to configure the permission of I2S0 accessing address, which is larger than boundary 1 and less than boundary 2, through EDMA. Bit 0: set this bit to enable read permission. Bit 1: set this bit to enable write permission.
  [1:0] ATTR1 — This field is used to configure the permission of I2S0 accessing address, which is larger than boundary 0 and less than boundary 1, through EDMA. Bit 0: set this bit to enable read permission. Bit 1: set this bit to enable write permission.
0x2D8 EDMA_PMS_I2S1_LOCK — EDMA-I2S1 permission lock register.
  [0] EDMA_PMS_I2S1_LOCK — Set 1 to lock EDMA-I2S1 permission control registers.
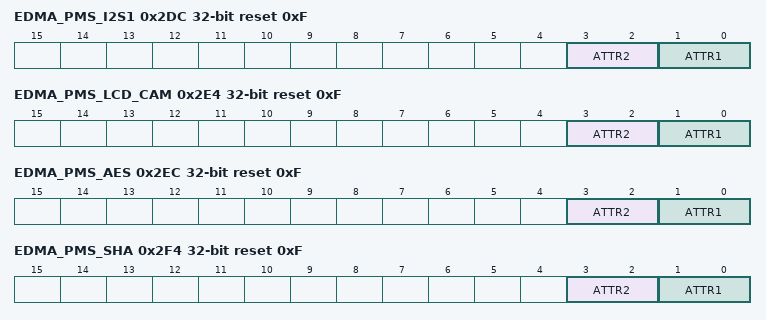
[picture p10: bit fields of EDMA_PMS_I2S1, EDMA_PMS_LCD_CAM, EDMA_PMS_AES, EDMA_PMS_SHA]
0x2DC EDMA_PMS_I2S1 reset 0xF — EDMA-I2S1 permission control register.
  [3:2] ATTR2 — This field is used to configure the permission of I2S1 accessing address, which is larger than boundary 1 and less than boundary 2, through EDMA. Bit 0: set this bit to enable read permission. Bit 1: set this bit to enable write permission.
  [1:0] ATTR1 — This field is used to configure the permission of I2S1 accessing address, which is larger than boundary 0 and less than boundary 1, through EDMA. Bit 0: set this bit to enable read permission. Bit 1: set this bit to enable write permission.
0x2E0 EDMA_PMS_LCD_CAM_LOCK — EDMA-LCD/CAM permission lock register.
  [0] EDMA_PMS_LCD_CAM_LOCK — Set 1 to lock EDMA-LCD/CAM permission control registers.
0x2E4 EDMA_PMS_LCD_CAM reset 0xF — EDMA-LCD/CAM permission control register.
  [3:2] ATTR2 — This field is used to configure the permission of LCD/CAM accessing address, which is larger than boundary 1 and less than boundary 2, through EDMA. Bit 0: set this bit to enable read permission. Bit 1: set this bit to enable write permission.
  [1:0] ATTR1 — This field is used to configure the permission of LCD/CAM accessing address, which is larger than boundary 0 and less than boundary 1, through EDMA. Bit 0: set this bit to enable read permission. Bit 1: set this bit to enable write permission.
0x2E8 EDMA_PMS_AES_LOCK — EDMA-AES permission lock register.
  [0] EDMA_PMS_AES_LOCK — Set 1 to lock EDMA-AES permission control registers.
0x2EC EDMA_PMS_AES reset 0xF — EDMA-AES permission control register.
  [3:2] ATTR2 — This field is used to configure the permission of AES accessing address, which is larger than boundary 1 and less than boundary 2, through EDMA. Bit 0: set this bit to enable read permission. Bit 1: set this bit to enable write permission.
  [1:0] ATTR1 — This field is used to configure the permission of AES accessing address, which is larger than boundary 0 and less than boundary 1, through EDMA. Bit 0: set this bit to enable read permission. Bit 1: set this bit to enable write permission.
0x2F0 EDMA_PMS_SHA_LOCK — EDMA-SHA permission lock register.
  [0] EDMA_PMS_SHA_LOCK — Set 1 to lock EDMA-SHA permission control registers.
0x2F4 EDMA_PMS_SHA reset 0xF — EDMA-SHA permission control register.
  [3:2] ATTR2 — This field is used to configure the permission of SHA accessing address, which is larger than boundary 1 and less than boundary 2, through EDMA. Bit 0: set this bit to enable read permission. Bit 1: set this bit to enable write permission.
  [1:0] ATTR1 — This field is used to configure the permission of SHA accessing address, which is larger than boundary 0 and less than boundary 1, through EDMA. Bit 0: set this bit to enable read permission. Bit 1: set this bit to enable write permission.
0x2F8 EDMA_PMS_ADC_DAC_LOCK — EDMA-ADC/DAC permission lock register.
  [0] EDMA_PMS_ADC_DAC_LOCK — Set 1 to lock EDMA-ADC/DAC permission control registers.
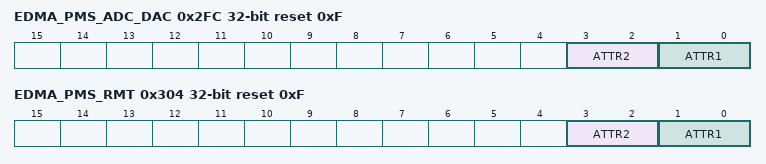
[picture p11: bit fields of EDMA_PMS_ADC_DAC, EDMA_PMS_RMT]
0x2FC EDMA_PMS_ADC_DAC reset 0xF — EDMA-ADC/DAC permission control register.
  [3:2] ATTR2 — This field is used to configure the permission of ADC/DAC accessing address, which is larger than boundary 1 and less than boundary 2, through EDMA. Bit 0: set this bit to enable read permission. Bit 1: set this bit to enable write permission.
  [1:0] ATTR1 — This field is used to configure the permission of ADC/DAC accessing address, which is larger than boundary 0 and less than boundary 1, through EDMA. Bit 0: set this bit to enable read permission. Bit 1: set this bit to enable write permission.
0x300 EDMA_PMS_RMT_LOCK — EDMA-RMT permission lock register.
  [0] EDMA_PMS_RMT_LOCK — Set 1 to lock EDMA-RMT permission control registers.
0x304 EDMA_PMS_RMT reset 0xF — EDMA-RMT permission control register.
  [3:2] ATTR2 — This field is used to configure the permission of RMT accessing address, which is larger than boundary 1 and less than boundary 2, through EDMA. Bit 0: set this bit to enable read permission. Bit 1: set this bit to enable write permission.
  [1:0] ATTR1 — This field is used to configure the permission of RMT accessing address, which is larger than boundary 0 and less than boundary 1, through EDMA. Bit 0: set this bit to enable read permission. Bit 1: set this bit to enable write permission.
0x308 CLOCK_GATE reset 0x1 — Sensitive module clock gate configuration register.
  [0] REG_CLK_EN — Set 1 to enable clock gate function.
0x30C RTC_PMS — RTC coprocessor permission register.
  [0] DIS_RTC_CPU — Set 1 to disable rtc coprocessor.
0xFFC DATE reset 0x2101280 — Sensitive version register.
  [27:0] DATE — Sensitive Date register.
